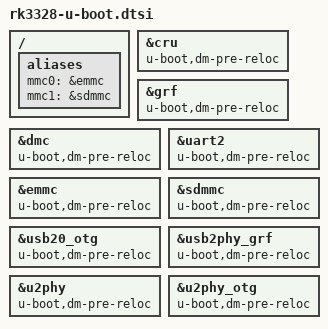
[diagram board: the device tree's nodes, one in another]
/*
 * (C) Copyright 2018 Rockchip Electronics Co., Ltd
 *
 * SPDX-License-Identifier:     GPL-2.0+
 */

/ {
	aliases {
		mmc0 = &emmc;
		mmc1 = &sdmmc;
	};
};

&cru {
	u-boot,dm-pre-reloc;
};

&grf {
	u-boot,dm-pre-reloc;
};

&dmc {
	u-boot,dm-pre-reloc;
};

&uart2 {
	u-boot,dm-pre-reloc;
};

&emmc {
	u-boot,dm-pre-reloc;
};

&sdmmc {
	u-boot,dm-pre-reloc;
};

&usb20_otg {
	u-boot,dm-pre-reloc;
};

&usb2phy_grf {
	u-boot,dm-pre-reloc;
};

&u2phy {
	u-boot,dm-pre-reloc;
};

&u2phy_otg {
	u-boot,dm-pre-reloc;
};
